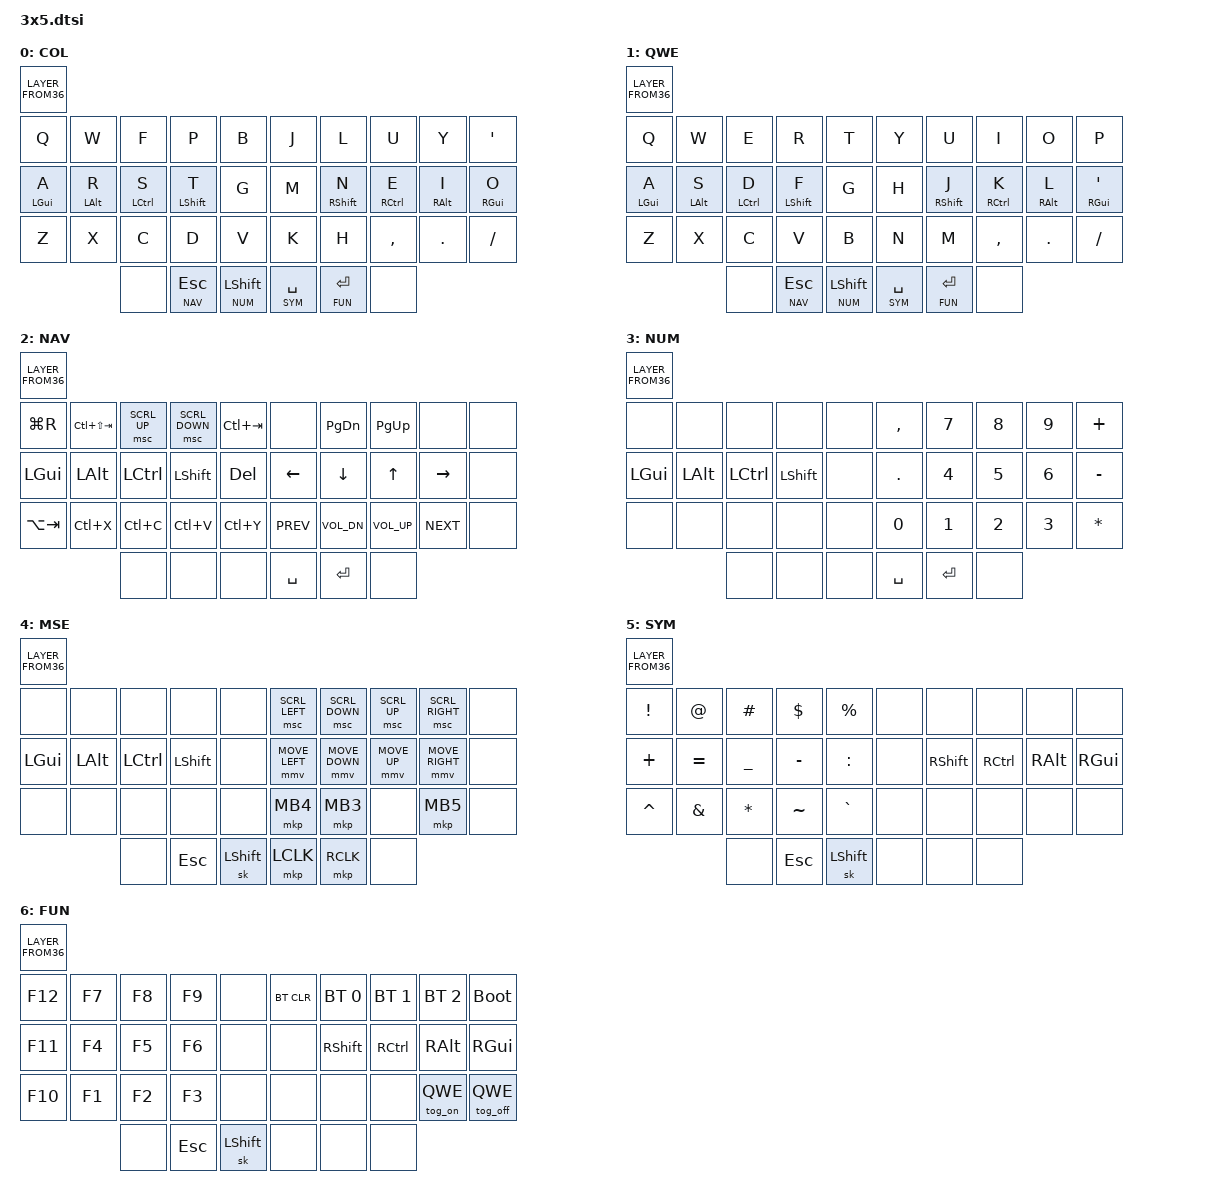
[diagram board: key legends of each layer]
#include <behaviors.dtsi>
#include <dt-bindings/zmk/bt.h>
#include <dt-bindings/zmk/keys.h>  
#include <dt-bindings/zmk/bt.h>
#include <dt-bindings/zmk/outputs.h>

#define COL 0
#define QWE 1
#define NAV 2
#define NUM 3
#define MSE 4
#define SYM 5
#define FUN 6

#include "combos.dtsi"
#include "mouse.dtsi"

#define XXX &none
#define ___ &trans

#define QUICK_TAP_MS 175
#define TAPPING_TERM_MS_HM 200
#define PRIOR_IDLE_MS_HM 150

&caps_word {
    continue-list = <UNDERSCORE MINUS BSPC DEL N1 N2 N3 N4 N5 N6 N7 N8 N9 N0>;
};

&sk {
    release-after-ms = <1000>;
    quick-release;
    /delete-property/ ignore-modifiers;
};

/ {
  behaviors {
    hml: home_row_mods_l {
      compatible = "zmk,behavior-hold-tap";
      #binding-cells = <2>;
      tapping-term-ms = <TAPPING_TERM_MS_HM>;
      // quick-tap-ms = <QUICK_TAP_MS>;
      flavor = "balanced";
      bindings = <&kp>, <&kp>;
      hold-trigger-key-positions = <KEYS_R THUMBS>;
      hold-trigger-on-release;
      require-prior-idle-ms = <PRIOR_IDLE_MS_HM>;
    };
    hmr: home_row_mods_r {
      compatible = "zmk,behavior-hold-tap";
      #binding-cells = <2>;
      tapping-term-ms = <TAPPING_TERM_MS_HM>;
      // quick-tap-ms = <QUICK_TAP_MS>;
      flavor = "balanced";
      bindings = <&kp>, <&kp>;
      hold-trigger-key-positions = <KEYS_L THUMBS>;
      hold-trigger-on-release;
      require-prior-idle-ms = <PRIOR_IDLE_MS_HM>;
    };
    lt: layer_tap {
      display-name = "Layer-Tap";
      compatible = "zmk,behavior-hold-tap";
      #binding-cells = <2>;
      tapping-term-ms = <200>;
      // quick-tap-ms = <QUICK_TAP_MS>;
      flavor = "balanced"; // <- maybe tap-preferred
      bindings = <&mo>, <&kp>;
    };        
    lts: layer_tap_sticky {
      display-name = "Layer-Tap";
      compatible = "zmk,behavior-hold-tap";
      #binding-cells = <2>;
      tapping-term-ms = <200>;
      // quick-tap-ms = <QUICK_TAP_MS>;
      flavor = "balanced";
      bindings = <&mo>, <&sk>;
    };        
    tog_on: toggle_layer_on_only {
      display-name = "Toggle Layer On";
      compatible = "zmk,behavior-toggle-layer";
      #binding-cells = <1>;
      toggle-mode = "on";
    };
    tog_off: toggle_layer_off_only {
      display-name = "Toggle Layer Off";
      compatible = "zmk,behavior-toggle-layer";
      #binding-cells = <1>;
      toggle-mode = "off";
    };
  };

  keymap {
    compatible = "zmk,keymap";

    default_layer {
      display-name = "COL";
      bindings = <LAYER_FROM36( \
// ╭─────────────┬─────────────┬─────────────┬─────────────┬─────────────╮   ╭─────────────┬─────────────┬─────────────┬─────────────┬─────────────╮
     &kp Q,        &kp W,        &kp F,        &kp P,        &kp B,            &kp J,        &kp L,        &kp U,        &kp Y,        &kp SQT,      \
// ├─────────────┼─────────────┼─────────────┼─────────────┼─────────────┤   ├─────────────┼─────────────┼─────────────┼─────────────┼─────────────┤
     &hml LGUI A,  &hml LALT R,  &hml LCTRL S, &hml LSHFT T, &kp G,            &kp M,        &hmr RSHFT N, &hmr RCTRL E, &hmr RALT I,  &hmr RGUI O,  \
// ├─────────────┼─────────────┼─────────────┼─────────────┼─────────────┤   ├─────────────┼─────────────┼─────────────┼─────────────┼─────────────┤
     &kp Z,        &kp X,        &kp C,        &kp D,        &kp V,            &kp K,        &kp H,        &kp COMMA,    &kp DOT,      &kp SLASH,    \
// ╰─────────────┴─────────────┴─────────────┼─────────────┼─────────────┤   ├─────────────┼─────────────┼─────────────┴─────────────┴─────────────╯
                                 XXX,          &lt NAV ESC,  &lts NUM LSHFT,  &lt SYM SPACE, &lt FUN RET,  XXX
//                             ╰─────────────┴─────────────┴─────────────╯   ╰─────────────┴─────────────┴─────────────╯
      )>;
    };

    qwerty_layer {
      display-name = "QWE";
      bindings = <LAYER_FROM36( \
// ╭─────────────┬─────────────┬─────────────┬─────────────┬─────────────╮   ╭─────────────┬─────────────┬─────────────┬─────────────┬─────────────╮
     &kp Q,        &kp W,        &kp E,        &kp R,        &kp T,            &kp Y,        &kp U,        &kp I,        &kp O,        &kp P,        \
// ├─────────────┼─────────────┼─────────────┼─────────────┼─────────────┤   ├─────────────┼─────────────┼─────────────┼─────────────┼─────────────┤
     &hml LGUI A,  &hml LALT S,  &hml LCTRL D, &hml LSHFT F, &kp G,            &kp H,        &hmr RSHFT J, &hmr RCTRL K, &hmr RALT L,  &hmr RGUI SQT,\
// ├─────────────┼─────────────┼─────────────┼─────────────┼─────────────┤   ├─────────────┼─────────────┼─────────────┼─────────────┼─────────────┤
     &kp Z,        &kp X,        &kp C,        &kp V,        &kp B,            &kp N,        &kp M,        &kp COMMA,    &kp DOT,      &kp FSLH,     \
// ╰─────────────┴─────────────┴─────────────┼─────────────┼─────────────┤   ├─────────────┼─────────────┼─────────────┴─────────────┴─────────────╯
                                 XXX,          &lt NAV ESC,  &lts NUM LSHFT,  &lt SYM SPACE, &lt FUN RET,  XXX
//                             ╰─────────────┴─────────────┴─────────────╯   ╰─────────────┴─────────────┴─────────────╯
      )>;      
    };

    nav_layer {
      display-name = "NAV";
      bindings = <LAYER_FROM36( \
// ╭─────────────┬─────────────┬─────────────┬─────────────┬─────────────╮   ╭─────────────┬─────────────┬─────────────┬─────────────┬─────────────╮
     &kp LG(R),  &kp LC(LS(TAB)),&msc SCRL_UP, &msc SCRL_DOWN,&kp LC(TAB),     XXX,          &kp PG_DN,    &kp PG_UP,    XXX,          XXX,          \
// ├─────────────┼─────────────┼─────────────┼─────────────┼─────────────┤   ├─────────────┼─────────────┼─────────────┼─────────────┼─────────────┤
     &kp LGUI,     &kp LALT,     &kp LCTRL,    &kp LSHFT,    &kp DEL,          &kp LEFT,     &kp DOWN,     &kp UP,       &kp RIGHT,    XXX,          \
// ├─────────────┼─────────────┼─────────────┼─────────────┼─────────────┤   ├─────────────┼─────────────┼─────────────┼─────────────┼─────────────┤
     &kp LA(TAB),  &kp LC(X),    &kp LC(C),    &kp LC(V),    &kp LC(Y),        &kp C_PREV,   &kp C_VOL_DN, &kp C_VOL_UP, &kp C_NEXT,  XXX,          \
// ╰─────────────┴─────────────┴─────────────┼─────────────┼─────────────┤   ├─────────────┼─────────────┼─────────────┴─────────────┴─────────────╯
                                 XXX,          XXX,          XXX,              &kp SPACE,     &kp RET,      XXX
//                             ╰─────────────┴─────────────┴─────────────╯   ╰─────────────┴─────────────┴─────────────╯
      )>;
    };

    num_layer {
      display-name = "NUM";
      bindings = <LAYER_FROM36( \
// ╭─────────────┬─────────────┬─────────────┬─────────────┬─────────────╮   ╭─────────────┬─────────────┬─────────────┬─────────────┬─────────────╮
     XXX,          XXX,          XXX,          XXX,          XXX,              &kp COMMA,    &kp N7,       &kp N8,       &kp N9,       &kp PLUS,     \
// ├─────────────┼─────────────┼─────────────┼─────────────┼─────────────┤   ├─────────────┼─────────────┼─────────────┼─────────────┼─────────────┤
     &kp LGUI,     &kp LALT,     &kp LCTRL,    &kp LSHFT,    XXX,              &kp DOT,      &kp N4,       &kp N5,       &kp N6,       &kp MINUS,    \
// ├─────────────┼─────────────┼─────────────┼─────────────┼─────────────┤   ├─────────────┼─────────────┼─────────────┼─────────────┼─────────────┤
     XXX,          XXX,          XXX,          XXX,          XXX,              &kp N0,       &kp N1,       &kp N2,       &kp N3,       &kp STAR,     \
// ╰─────────────┴─────────────┴─────────────┼─────────────┼─────────────┤   ├─────────────┼─────────────┼─────────────┴─────────────┴─────────────╯
                                 XXX,          XXX,          XXX,              &kp SPACE,     &kp RET,      XXX
//                             ╰─────────────┴─────────────┴─────────────╯   ╰─────────────┴─────────────┴─────────────╯
      )>;
    };

    mouse_layer {
      display-name = "MSE";
      bindings = <LAYER_FROM36( \
// ╭─────────────┬─────────────┬─────────────┬─────────────┬─────────────╮   ╭─────────────┬─────────────┬─────────────┬─────────────┬─────────────╮
     XXX,          XXX,          XXX,          XXX,          XXX,           &msc SCRL_LEFT, &msc SCRL_DOWN,&msc SCRL_UP,&msc SCRL_RIGHT,XXX,         \
// ├─────────────┼─────────────┼─────────────┼─────────────┼─────────────┤   ├─────────────┼─────────────┼─────────────┼─────────────┼─────────────┤
     &kp LGUI,     &kp LALT,     &kp LCTRL,    &kp LSHFT,    XXX,           &mmv MOVE_LEFT, &mmv MOVE_DOWN,&mmv MOVE_UP,&mmv MOVE_RIGHT,XXX,         \
// ├─────────────┼─────────────┼─────────────┼─────────────┼─────────────┤   ├─────────────┼─────────────┼─────────────┼─────────────┼─────────────┤
     XXX,          XXX,          XXX,          XXX,          XXX,              &mkp MB4,     &mkp MB3,      XXX,         &mkp MB5,     XXX,          \
// ╰─────────────┴─────────────┴─────────────┼─────────────┼─────────────┤   ├─────────────┼─────────────┼─────────────┴─────────────┴─────────────╯
                                 XXX,          &kp ESC,      &sk LSHFT,        &mkp LCLK,    &mkp RCLK,    XXX
//                             ╰─────────────┴─────────────┴─────────────╯   ╰─────────────┴─────────────┴─────────────╯
      )>;
    };

    symbol_layer {
      display-name = "SYM";
      bindings = <LAYER_FROM36( \
// ╭─────────────┬─────────────┬─────────────┬─────────────┬─────────────╮   ╭─────────────┬─────────────┬─────────────┬─────────────┬─────────────╮
     &kp EXCL,     &kp AT,       &kp HASH,     &kp DLLR,     &kp PRCNT,        XXX,          XXX,          XXX,          XXX,          XXX,          \
// ├─────────────┼─────────────┼─────────────┼─────────────┼─────────────┤   ├─────────────┼─────────────┼─────────────┼─────────────┼─────────────┤
     &kp PLUS,     &kp EQUAL,    &kp UNDER,    &kp MINUS,    &kp COLON,        XXX,          &kp RSHFT,    &kp RCTRL,    &kp RALT,     &kp RGUI,     \
// ├─────────────┼─────────────┼─────────────┼─────────────┼─────────────┤   ├─────────────┼─────────────┼─────────────┼─────────────┼─────────────┤
     &kp CARET,    &kp AMPS,     &kp STAR,     &kp TILDE,    &kp GRAVE,        XXX,          XXX,          XXX,          XXX,          XXX,          \
// ╰─────────────┴─────────────┴─────────────┼─────────────┼─────────────┤   ├─────────────┼─────────────┼─────────────┴─────────────┴─────────────╯
                                 XXX,          &kp ESC,      &sk LSHFT,        XXX,          XXX,          XXX
//                             ╰─────────────┴─────────────┴─────────────╯   ╰─────────────┴─────────────┴─────────────╯
      )>;
    };

    fun_layer {
      display-name = "FUN";
      bindings = <LAYER_FROM36( \
// ╭─────────────┬─────────────┬─────────────┬─────────────┬─────────────╮   ╭─────────────┬─────────────┬─────────────┬─────────────┬─────────────╮
     &kp F12,      &kp F7,       &kp F8,       &kp F9,       XXX,              &bt BT_CLR,   &bt BT_SEL 0, &bt BT_SEL 1, &bt BT_SEL 2, &bootloader,  \
// ├─────────────┼─────────────┼─────────────┼─────────────┼─────────────┤   ├─────────────┼─────────────┼─────────────┼─────────────┼─────────────┤
     &kp F11,      &kp F4,       &kp F5,       &kp F6,       XXX,              XXX,          &kp RSHFT,    &kp RCTRL,    &kp RALT,     &kp RGUI,     \
// ├─────────────┼─────────────┼─────────────┼─────────────┼─────────────┤   ├─────────────┼─────────────┼─────────────┼─────────────┼─────────────┤
     &kp F10,      &kp F1,       &kp F2,       &kp F3,       XXX,              XXX,          XXX,          XXX,          &tog_on QWE,  &tog_off QWE, \
// ╰─────────────┴─────────────┴─────────────┼─────────────┼─────────────┤   ├─────────────┼─────────────┼─────────────┴─────────────┴─────────────╯
                                 XXX,          &kp ESC,      &sk LSHFT,        XXX,          XXX,          XXX
//                             ╰─────────────┴─────────────┴─────────────╯   ╰─────────────┴─────────────┴─────────────╯
      )>;
    };
  };
};
